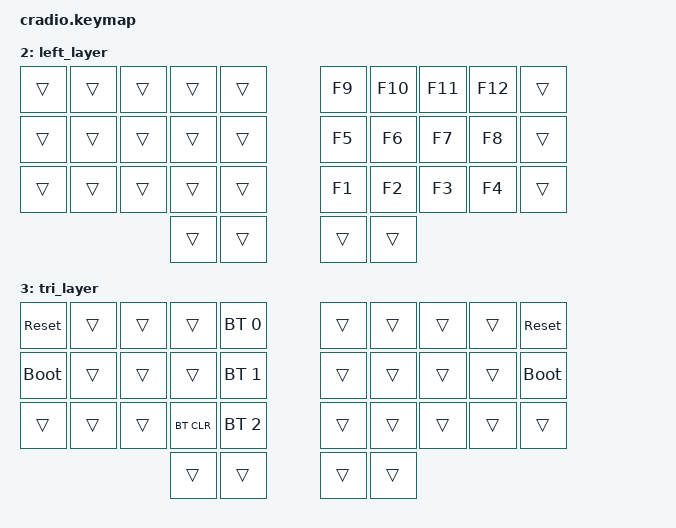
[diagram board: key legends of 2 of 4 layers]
// Copyright (c) 2022 The ZMK Contributors
// SPDX-License-Identifier: MIT

#include <behaviors.dtsi>
#include <dt-bindings/zmk/keys.h>
#include <dt-bindings/zmk/bt.h>

// Home row mods macro
#define HRML(k1,k2,k3,k4) &ht LSHFT k1  &ht LALT k2  &ht LGUI k3  &ht LCTRL k4
#define HRMR(k1,k2,k3,k4) &ht LCTRL k1  &ht RGUI k2  &ht RALT k3  &ht RSHFT k4

/ {
    behaviors {
        ht: hold_tap {
            compatible = "zmk,behavior-hold-tap";
            #binding-cells = <2>;
            flavor = "tap-preferred";
            tapping-term-ms = <200>;
            quick-tap-ms = <150>;
            require-prior-idle-ms = <100>;
            bindings = <&kp>, <&kp>;
        };
    };

    combos {
        compatible = "zmk,combos";
        combo_ralt {
            timeout-ms = <50>;
            key-positions = <16 17>;
            bindings = <&kp RALT>;
        };
        combo_caps {
            timeout-ms = <50>;
            key-positions = <12 13>;
            bindings = <&kp CAPS>;
        };
        combo_lang {
            timeout-ms = <50>;
            key-positions = <30 31>;
            bindings = <&langhold>;
        };
    };

    conditional_layers {
        compatible = "zmk,conditional-layers";
        tri_layer {
            if-layers = <1 2>;
            then-layer = <3>;
        };
    };

    macros {
        langhold: langhold {
            compatible = "zmk,behavior-macro";
            label = "ZM_langhold";
            #binding-cells = <0>;
            bindings
            = <&macro_press &kp CAPS>
            , <&macro_pause_for_release>
            , <&macro_release &kp CAPS>
            ;
        };
    };

    keymap {
        compatible = "zmk,keymap";
        default_layer {
            bindings = <
        //╭──────────┬──────────┬──────────┬──────────┬──────────╮   ╭──────────┬──────────┬──────────┬──────────┬──────────╮
        //│  Q       │  W       │  E       │  R       │  T       │   │  Y       │  U       │  I       │  O       │  P       │
            &kp Q      &kp W      &kp E      &kp R      &kp T          &kp Y      &kp U      &kp I      &kp O      &kp P
        //├──────────┼──────────┼──────────┼──────────┼──────────┤   ├──────────┼──────────┼──────────┼──────────┼──────────┤
        //│  A       │  S       │  D       │  F       │  G       │   │  H       │  J       │  K       │  L       │ ; :      │
            HRML(A,        S,         D,         F)     &kp G          &kp H      HRMR(J,        K,         L,        SEMI)
        //├──────────┼──────────┼──────────┼──────────┼──────────┤   ├──────────┼──────────┼──────────┼──────────┼──────────┤
        //│  Z       │  X       │  C       │  V       │  B       │   │  N       │  M       │ , <      │ . >      │ / ?      │
            &kp Z      &kp X      &kp C      &kp V      &kp B          &kp N      &kp M      &kp COMMA  &kp DOT    &kp FSLH
        //╰──────────┴──────────┴──────────┼──────────┼──────────┤   ├──────────┼──────────┼──────────┴──────────┴──────────╯
                                             &kp TAB    &lt 1 SPACE    &lt 1 ENTER &lt 2 BSPC
        //                                 ╰──────────┴──────────╯   ╰──────────┴──────────╯
            >;
        };

        right_layer {
            bindings = <
        //╭──────────┬──────────┬──────────┬──────────┬──────────╮   ╭──────────┬──────────┬──────────┬──────────┬──────────╮
        //│ ESC      │  7       │  8       │  9       │  -       │   │ LBKT     │ HOME     │ UP       │ END      │          │
            &kp ESC     &kp N7     &kp N8     &kp N9     &kp MINUS     &kp LBKT   &kp HOME   &kp UP     &kp END    &trans
        //├──────────┼──────────┼──────────┼──────────┼──────────┤   ├──────────┼──────────┼──────────┼──────────┼──────────┤
        //│          │  4       │  5       │  6       │  =       │   │ RBKT     │ LEFT     │ DOWN     │ RIGHT    │ ' "      │
            HRML(A,     N4,        N5,        N6)        &kp EQUAL     &kp RBKT   HRMR(LEFT, DOWN,      RIGHT,     SQT)
        //├──────────┼──────────┼──────────┼──────────┼──────────┤   ├──────────┼──────────┼──────────┼──────────┼──────────┤
        //│ BSLH     │  1       │  2       │  3       │  0       │   │          │          │          │          │          │
            &kp BSLH    &kp N1     &kp N2     &kp N3     &kp GRAVE     &trans     &trans     &trans     &trans     &trans
        //╰──────────┴──────────┴──────────┼──────────┼──────────┤   ├──────────┼──────────┼──────────┴──────────┴──────────╯
                                             &kp N0      &trans        &trans     &kp DEL
        //                                 ╰──────────┴──────────╯   ╰──────────┴──────────╯
            >;
        };

        left_layer {
            bindings = <
        //╭──────────┬──────────┬──────────┬──────────┬──────────╮   ╭──────────┬──────────┬──────────┬──────────┬──────────╮
        //│          │          │          │          │          │   │ F9       │ F10      │ F11      │ F12      │          │
            &trans     &trans     &trans     &trans     &trans         &kp F9     &kp F10    &kp F11    &kp F12    &trans
        //├──────────┼──────────┼──────────┼──────────┼──────────┤   ├──────────┼──────────┼──────────┼──────────┼──────────┤
        //│          │          │          │          │          │   │ F5       │  F6      │  F7      │  F8      │          │
            &trans     &trans     &trans     &trans     &trans         &kp F5      &kp F6     &kp F7     &kp F8    &trans
        //├──────────┼──────────┼──────────┼──────────┼──────────┤   ├──────────┼──────────┼──────────┼──────────┼──────────┤
        //│          │          │          │          │          │   │ F1       │  F2      │  F3      │  F4      │          │
            &trans     &trans     &trans     &trans     &trans         &kp F1      &kp F2     &kp F3     &kp F4    &trans
        //╰──────────┴──────────┴──────────┼──────────┼──────────┤   ├──────────┼──────────┼──────────┴──────────┴──────────╯
                                             &trans     &trans         &trans     &trans
        //                                 ╰──────────┴──────────╯   ╰──────────┴──────────╯
            >;
        };

        tri_layer {
            bindings = <
        //╭──────────┬──────────┬──────────┬──────────┬──────────╮   ╭──────────┬──────────┬──────────┬──────────┬──────────╮
        //│ RESET    │          │          │          │PROFILE 0 │   │          │          │          │          │  RESET   │
           &sys_reset  &trans     &trans     &trans    &bt BT_SEL 0    &trans     &trans     &trans     &trans    &sys_reset
        //├──────────┼──────────┼──────────┼──────────┼──────────┤   ├──────────┼──────────┼──────────┼──────────┼──────────┤
        //│BOOTLOADER│          │          │          │PROFILE 1 │   │          │          │          │          │BOOTLOADER│
          &bootloader  &trans     &trans     &trans    &bt BT_SEL 1    &trans     &trans     &trans     &trans    &bootloader
        //├──────────┼──────────┼──────────┼──────────┼──────────┤   ├──────────┼──────────┼──────────┼──────────┼──────────┤
        //│          │          │          │ CLEAR BT │PROFILE 2 │   │          │          │          │          │          │
            &trans     &trans     &trans    &bt BT_CLR &bt BT_SEL 2    &trans     &trans     &trans     &trans     &trans
        //╰──────────┴──────────┴──────────┼──────────┼──────────┤   ├──────────┼──────────┼──────────┴──────────┴──────────╯
                                             &trans     &trans         &trans     &trans
        //                                 ╰──────────┴──────────╯   ╰──────────┴──────────╯
            >;
        };
    };
};
